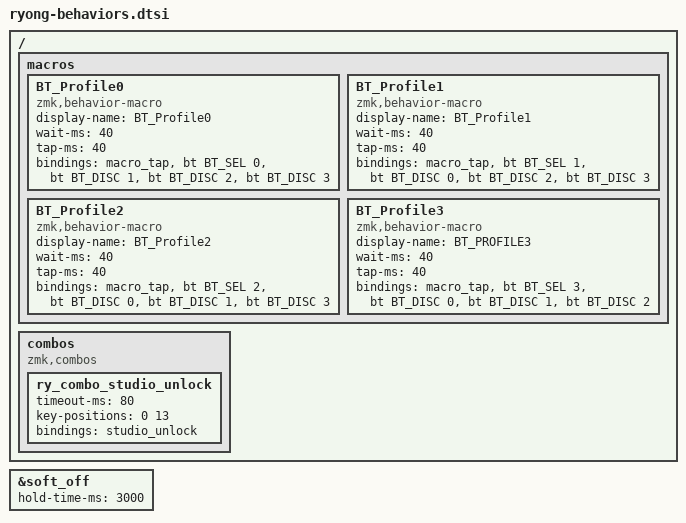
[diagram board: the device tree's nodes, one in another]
/*
 * Generated by key.ryong.com — edit in the Behaviors editor, not by hand.
 * Source of truth: ryong-behaviors.json in this folder.
 */

#include <dt-bindings/zmk/keys.h>
#include <dt-bindings/zmk/bt.h>
#include <dt-bindings/zmk/outputs.h>

&soft_off {
    hold-time-ms = <3000>;
};

/ {
    macros {
        BT_Profile0: BT_Profile0 {
            compatible = "zmk,behavior-macro";
            #binding-cells = <0>;
            display-name = "BT_Profile0";
            wait-ms = <40>;
            tap-ms = <40>;
            bindings
                = <&macro_tap &bt BT_SEL 0 &bt BT_DISC 1 &bt BT_DISC 2 &bt BT_DISC 3>
                ;
        };
        BT_Profile1: BT_Profile1 {
            compatible = "zmk,behavior-macro";
            #binding-cells = <0>;
            display-name = "BT_Profile1";
            wait-ms = <40>;
            tap-ms = <40>;
            bindings
                = <&macro_tap &bt BT_SEL 1 &bt BT_DISC 0 &bt BT_DISC 2 &bt BT_DISC 3>
                ;
        };
        BT_Profile2: BT_Profile2 {
            compatible = "zmk,behavior-macro";
            #binding-cells = <0>;
            display-name = "BT_Profile2";
            wait-ms = <40>;
            tap-ms = <40>;
            bindings
                = <&macro_tap &bt BT_SEL 2 &bt BT_DISC 0 &bt BT_DISC 1 &bt BT_DISC 3>
                ;
        };
        BT_Profile3: BT_Profile3 {
            compatible = "zmk,behavior-macro";
            #binding-cells = <0>;
            display-name = "BT_PROFILE3";
            wait-ms = <40>;
            tap-ms = <40>;
            bindings
                = <&macro_tap &bt BT_SEL 3 &bt BT_DISC 0 &bt BT_DISC 1 &bt BT_DISC 2>
                ;
        };
    };

    combos {
        compatible = "zmk,combos";
        ry_combo_studio_unlock {
            timeout-ms = <80>;
            key-positions = <0 13>;
            bindings = <&studio_unlock>;
        };
    };
};
